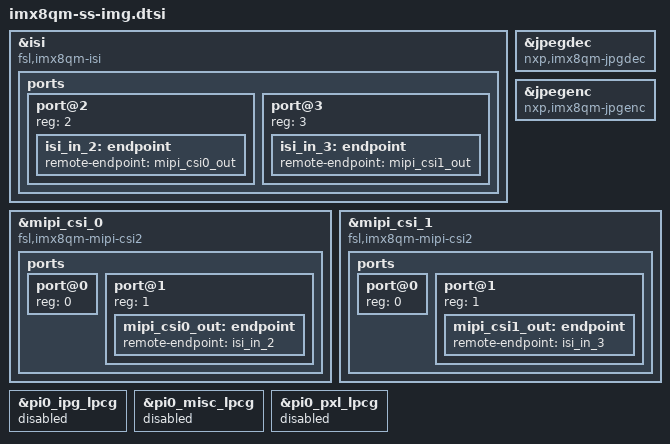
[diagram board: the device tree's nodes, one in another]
// SPDX-License-Identifier: GPL-2.0+
/*
 * Copyright 2021 NXP
 */

&isi {
	compatible = "fsl,imx8qm-isi";

	ports {
		#address-cells = <1>;
		#size-cells = <0>;

		port@2 {
			reg = <2>;

			isi_in_2: endpoint {
				remote-endpoint = <&mipi_csi0_out>;
			};
		};

		port@3 {
			reg = <3>;

			isi_in_3: endpoint {
				remote-endpoint = <&mipi_csi1_out>;
			};
		};
	};
};

&jpegdec {
	compatible = "nxp,imx8qm-jpgdec", "nxp,imx8qxp-jpgdec";
};

&jpegenc {
	compatible = "nxp,imx8qm-jpgenc", "nxp,imx8qxp-jpgenc";
};

&mipi_csi_0 {
	compatible = "fsl,imx8qm-mipi-csi2", "fsl,imx8qxp-mipi-csi2";

	ports {
		#address-cells = <1>;
		#size-cells = <0>;

		port@0 {
			reg = <0>;
		};

		port@1 {
			reg = <1>;

			mipi_csi0_out: endpoint {
				remote-endpoint = <&isi_in_2>;
			};
		};
	};
};

&mipi_csi_1 {
	compatible = "fsl,imx8qm-mipi-csi2", "fsl,imx8qxp-mipi-csi2";

	ports {
		#address-cells = <1>;
		#size-cells = <0>;

		port@0 {
			reg = <0>;
		};

		port@1 {
			reg = <1>;

			mipi_csi1_out: endpoint {
				remote-endpoint = <&isi_in_3>;
			};
		};
	};
};

&pi0_ipg_lpcg {
	status = "disabled";
};

&pi0_misc_lpcg {
	status = "disabled";
};

&pi0_pxl_lpcg {
	status = "disabled";
};
